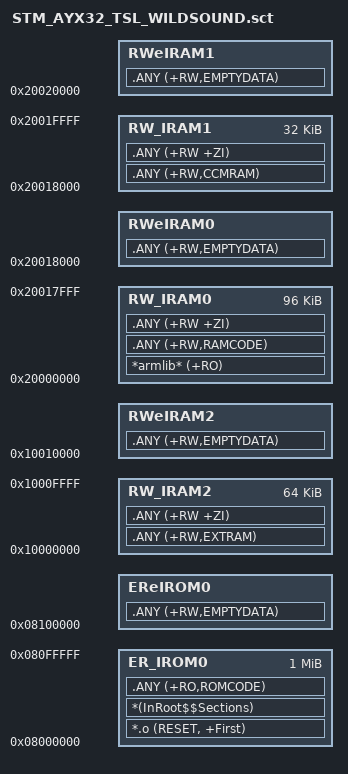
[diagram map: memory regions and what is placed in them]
;;;;;;;;;;;;;;;;;;;;;;;;;;;;;;;;;;;;;;;;;;;;;;;;;;;;;;;;;;;;;;;
;;;; Scatter-Loading Description File Created By Rob F. ;;;;;;;
;;;;;;;;;;;;;;;;;;;;;;;;;;;;;;;;;;;;;;;;;;;;;;;;;;;;;;;;;;;;;;;

LR_IROM 0x08000000 0x00100000  {    ; load region size_region
    ;;;;;;;;;;;;;;;;;;;;;;;;;;;;;;;;;;
    ;FLAH REGION #0
      ER_IROM0 0x08000000 0x00100000  {  ; RO data
       *.o (RESET, +First)
       *(InRoot$$Sections)
       .ANY (+RO,ROMCODE)
    } EReIROM0 0x08100000 0x00000000  {.ANY (+RW,EMPTYDATA)}
    ;;;;;;;;;;;;;;;;;;;;;;;;;;;;;;;;;;
    ;RAM REGION #0
      RW_IRAM0 0x20000000 0x00018000  {  ; RW data
       *armlib* (+RO)
       .ANY (+RW,RAMCODE)
       .ANY (+RW +ZI)
    } RWeIRAM0 0x20018000 0x00000000  {.ANY (+RW,EMPTYDATA)}
    ;;;;;;;;;;;;;;;;;;;;;;;;;;;;;;;;;;
    ;RAM REGION #1
      RW_IRAM1 0x20018000 0x00008000  {  ; RW data
       .ANY (+RW,CCMRAM)
       .ANY (+RW +ZI)
    } RWeIRAM1 0x20020000 0x00000000  {.ANY (+RW,EMPTYDATA)}
    ;;;;;;;;;;;;;;;;;;;;;;;;;;;;;;;;;;
    ;RAM REGION #2
      RW_IRAM2 0x10000000 0x00010000  {  ; RW data
       .ANY (+RW,EXTRAM)
       .ANY (+RW +ZI)
    } RWeIRAM2 0x10010000 0x00000000  {.ANY (+RW,EMPTYDATA)}
    ;;;;;;;;;;;;;;;;;;;;;;;;;;;;;;;;;;
}

